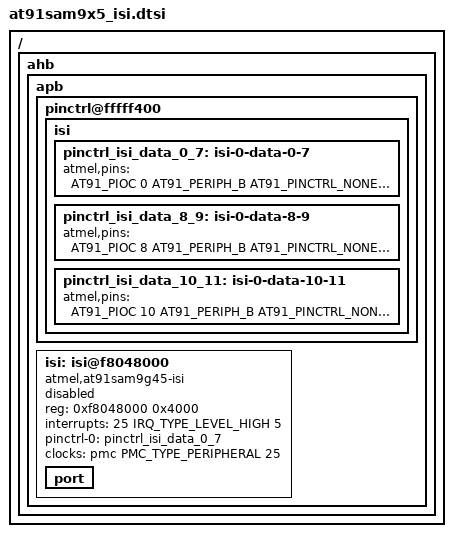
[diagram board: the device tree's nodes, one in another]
#include <dt-bindings/pinctrl/at91.h>
#include <dt-bindings/interrupt-controller/irq.h>
/ {
	ahb {
		apb {
			pinctrl@fffff400 {
				isi {
					pinctrl_isi_data_0_7: isi-0-data-0-7 {
						atmel,pins =
							<AT91_PIOC 0 AT91_PERIPH_B AT91_PINCTRL_NONE	 
							AT91_PIOC 1 AT91_PERIPH_B AT91_PINCTRL_NONE	 
							AT91_PIOC 2 AT91_PERIPH_B AT91_PINCTRL_NONE	 
							AT91_PIOC 3 AT91_PERIPH_B AT91_PINCTRL_NONE	 
							AT91_PIOC 4 AT91_PERIPH_B AT91_PINCTRL_NONE	 
							AT91_PIOC 5 AT91_PERIPH_B AT91_PINCTRL_NONE	 
							AT91_PIOC 6 AT91_PERIPH_B AT91_PINCTRL_NONE	 
							AT91_PIOC 7 AT91_PERIPH_B AT91_PINCTRL_NONE	 
							AT91_PIOC 12 AT91_PERIPH_B AT91_PINCTRL_NONE	 
							AT91_PIOC 14 AT91_PERIPH_B AT91_PINCTRL_NONE	 
							AT91_PIOC 13 AT91_PERIPH_B AT91_PINCTRL_NONE>;	 
					};
					pinctrl_isi_data_8_9: isi-0-data-8-9 {
						atmel,pins =
							<AT91_PIOC 8 AT91_PERIPH_B AT91_PINCTRL_NONE	 
							AT91_PIOC 9 AT91_PERIPH_B AT91_PINCTRL_NONE>;	 
					};
					pinctrl_isi_data_10_11: isi-0-data-10-11 {
						atmel,pins =
							<AT91_PIOC 10 AT91_PERIPH_B AT91_PINCTRL_NONE	 
							AT91_PIOC 11 AT91_PERIPH_B AT91_PINCTRL_NONE>;	 
					};
				};
			};
			isi: isi@f8048000 {
				compatible = "atmel,at91sam9g45-isi";
				reg = <0xf8048000 0x4000>;
				interrupts = <25 IRQ_TYPE_LEVEL_HIGH 5>;
				pinctrl-names = "default";
				pinctrl-0 = <&pinctrl_isi_data_0_7>;
				clocks = <&pmc PMC_TYPE_PERIPHERAL 25>;
				clock-names = "isi_clk";
				status = "disabled";
				port {
					#address-cells = <1>;
					#size-cells = <0>;
				};
			};
		};
	};
};
